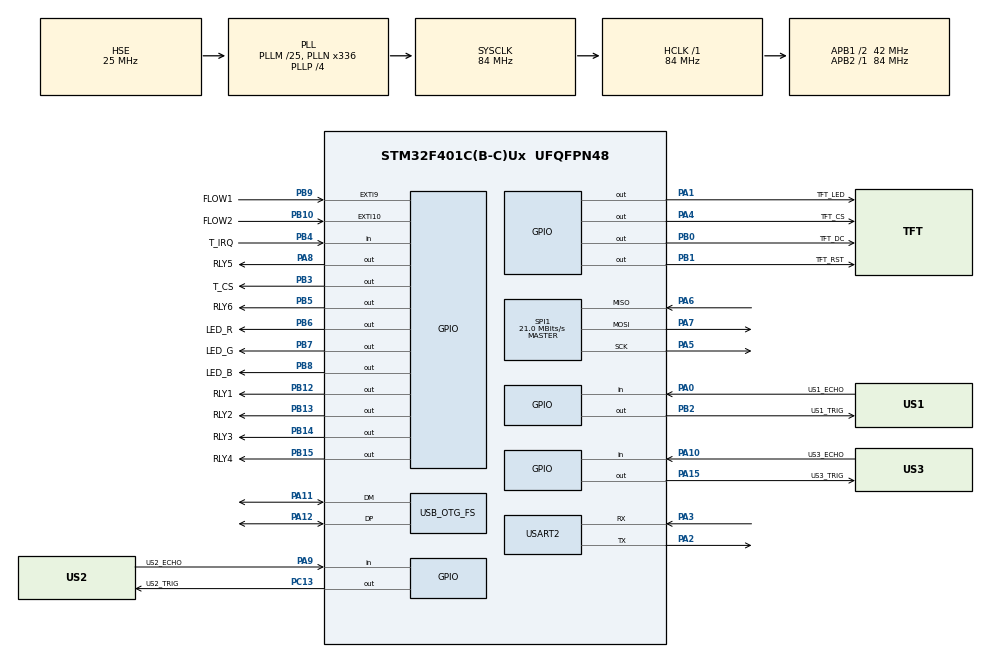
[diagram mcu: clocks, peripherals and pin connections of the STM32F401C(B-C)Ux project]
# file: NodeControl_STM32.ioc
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FREERTOS.Tasks01=defaultTask,0,128,StartDefaultTask,Default,NULL,Dynamic,NULL,NULL;TaskTelemetry,0,512,StartTaskTelemetry,Default,NULL,Dynamic,NULL,NULL;TaskIrrigation,0,512,StartTaskIrrigation,Default,NULL,Dynamic,NULL,NULL
FREERTOS.configUSE_NEWLIB_REENTRANT=1
Mcu.Family=STM32F4
Mcu.Name=STM32F401C(B-C)Ux
Mcu.Package=UFQFPN48
NVIC.EXTI15_10_IRQn=true\:5\:0\:false\:false\:true\:true\:true\:true\:true
NVIC.EXTI9_5_IRQn=true\:5\:0\:false\:false\:true\:true\:true\:true\:true
NVIC.OTG_FS_IRQn=true\:5\:0\:false\:false\:true\:true\:false\:true\:true
NVIC.PriorityGroup=NVIC_PRIORITYGROUP_4
NVIC.TIM5_IRQn=true\:15\:0\:false\:false\:true\:false\:false\:true\:true
NVIC.TimeBase=TIM5_IRQn
NVIC.TimeBaseIP=TIM5
NVIC.USART2_IRQn=true\:5\:0\:false\:false\:true\:true\:true\:true\:true
PA0-WKUP.GPIO_Label=US1_ECHO
PA0-WKUP.Signal=GPIO_Input
PA1.GPIO_Label=TFT_LED
PA1.PinState=GPIO_PIN_SET
PA1.Signal=GPIO_Output
PA10.GPIO_Label=US3_ECHO
PA10.Signal=GPIO_Input
PA11.Mode=Device_Only
PA11.Signal=USB_OTG_FS_DM
PA12.Mode=Device_Only
PA12.Signal=USB_OTG_FS_DP
PA13.Mode=Serial_Wire
PA13.Signal=SYS_JTMS-SWDIO
PA14.Mode=Serial_Wire
PA14.Signal=SYS_JTCK-SWCLK
PA15.GPIO_Label=US3_TRIG
PA15.GPIO_Speed=GPIO_SPEED_FREQ_HIGH
PA15.Signal=GPIO_Output
PA2.Mode=Asynchronous
PA2.Signal=USART2_TX
PA3.Mode=Asynchronous
PA3.Signal=USART2_RX
PA4.GPIO_Label=TFT_CS
PA4.GPIO_Speed=GPIO_SPEED_FREQ_VERY_HIGH
PA4.PinState=GPIO_PIN_SET
PA4.Signal=GPIO_Output
PA5.Mode=Full_Duplex_Master
PA5.Signal=SPI1_SCK
PA6.Mode=Full_Duplex_Master
PA6.Signal=SPI1_MISO
PA7.Mode=Full_Duplex_Master
PA7.Signal=SPI1_MOSI
PA8.GPIO_Label=RLY5
PA8.Signal=GPIO_Output
PA9.GPIO_Label=US2_ECHO
PA9.Signal=GPIO_Input
PB0.GPIO_Label=TFT_DC
PB0.GPIO_Speed=GPIO_SPEED_FREQ_VERY_HIGH
PB0.Signal=GPIO_Output
PB1.GPIO_Label=TFT_RST
PB1.GPIO_Speed=GPIO_SPEED_FREQ_VERY_HIGH
PB1.PinState=GPIO_PIN_SET
PB1.Signal=GPIO_Output
PB10.GPIO_Label=FLOW2
PB10.Signal=GPXTI10
PB12.GPIO_Label=RLY1
PB12.Signal=GPIO_Output
PB13.GPIO_Label=RLY2
PB13.Signal=GPIO_Output
PB14.GPIO_Label=RLY3
PB14.Signal=GPIO_Output
PB15.GPIO_Label=RLY4
PB15.Signal=GPIO_Output
PB2.GPIO_Label=US1_TRIG
PB2.GPIO_Speed=GPIO_SPEED_FREQ_HIGH
PB2.PinState=GPIO_PIN_RESET
PB2.Signal=GPIO_Output
PB3.GPIO_Label=T_CS
PB3.GPIO_Speed=GPIO_SPEED_FREQ_VERY_HIGH
PB3.PinState=GPIO_PIN_SET
PB3.Signal=GPIO_Output
PB4.GPIO_Label=T_IRQ
PB4.Signal=GPIO_Input
PB5.GPIO_Label=RLY6
PB5.Signal=GPIO_Output
PB6.GPIO_Label=LED_R
PB6.Signal=GPIO_Output
PB7.GPIO_Label=LED_G
PB7.Signal=GPIO_Output
PB8.GPIO_Label=LED_B
PB8.Signal=GPIO_Output
PB9.GPIO_Label=FLOW1
PB9.Signal=GPXTI9
PC13-ANTI_TAMP.GPIO_Label=US2_TRIG
PC13-ANTI_TAMP.Signal=GPIO_Output
PH0\ -\ OSC_IN.Mode=HSE-External-Oscillator
PH0\ -\ OSC_IN.Signal=RCC_OSC_IN
PH1\ -\ OSC_OUT.Mode=HSE-External-Oscillator
PH1\ -\ OSC_OUT.Signal=RCC_OSC_OUT
ProjectManager.HeapSize=0x200
ProjectManager.StackSize=0x400
ProjectManager.TargetToolchain=STM32CubeIDE
RCC.48MHZClocksFreq_Value=48000000
RCC.AHBFreq_Value=84000000
RCC.APB1CLKDivider=RCC_HCLK_DIV2
RCC.APB1Freq_Value=42000000
RCC.APB1TimFreq_Value=84000000
RCC.APB2Freq_Value=84000000
RCC.APB2TimFreq_Value=84000000
RCC.CortexFreq_Value=84000000
RCC.HCLKFreq_Value=84000000
RCC.HSE_VALUE=25000000
RCC.HSI_VALUE=16000000
RCC.LSE_VALUE=32768
RCC.PLLM=25
RCC.PLLN=336
RCC.PLLP=RCC_PLLP_DIV4
RCC.PLLQ=7
RCC.SYSCLKFreq_VALUE=84000000
RCC.SYSCLKSource=RCC_SYSCLKSOURCE_PLLCLK
RCC.VCOOutputFreq_Value=336000000
SPI1.BaudRatePrescaler=SPI_BAUDRATEPRESCALER_4
SPI1.CalculateBaudRate=21.0 MBits/s
SPI1.Direction=SPI_DIRECTION_2LINES
SPI1.Mode=SPI_MODE_MASTER
SPI1.VirtualType=VM_MASTER
USART2.VirtualMode=VM_ASYNC
USB_DEVICE.CLASS_NAME_FS=CDC
USB_DEVICE.VirtualMode=Cdc
USB_DEVICE.VirtualModeFS=Cdc_FS
USB_OTG_FS.VirtualMode=Device_Only
VP_FREERTOS_VS_CMSIS_V1.Mode=CMSIS_V1
VP_RTC_VS_RTC_Activate.Mode=RTC_Enabled
VP_SYS_VS_tim5.Mode=TIM5
VP_USB_DEVICE_VS_USB_DEVICE_CDC_FS.Mode=CDC_FS
board=custom

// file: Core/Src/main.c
/* USER CODE BEGIN Header */
/**
  ******************************************************************************
  * @file           : main.c
  * @brief          : Main program body
  ******************************************************************************
  * @attention
  *
  * Copyright (c) 2026 STMicroelectronics.
  * All rights reserved.
  *
  * This software is licensed under terms that can be found in the LICENSE file
  * in the root directory of this software component.
  * If no LICENSE file comes with this software, it is provided AS-IS.
  *
  ******************************************************************************
  */
/* USER CODE END Header */
#include "main.h"
#include "cmsis_os.h"
#include "usb_device.h"

/* USER CODE BEGIN Includes */
#include "app_rtos.h"
/* USER CODE END Includes */

RTC_HandleTypeDef hrtc;

SPI_HandleTypeDef hspi1;

UART_HandleTypeDef huart2;

osThreadId defaultTaskHandle;
osThreadId TaskTelemetryHandle;
osThreadId TaskIrrigationHandle;

void SystemClock_Config(void);
static void MX_GPIO_Init(void);
static void MX_RTC_Init(void);
static void MX_SPI1_Init(void);
static void MX_USART2_UART_Init(void);
void StartDefaultTask(void const * argument);
void StartTaskTelemetry(void const * argument);
void StartTaskIrrigation(void const * argument);

int main(void)
{

  /* MCU Configuration--------------------------------------------------------*/

  /* Reset of all peripherals, Initializes the Flash interface and the Systick. */
  HAL_Init();

  /* Configure the system clock */
  SystemClock_Config();

  /* Initialize all configured peripherals */
  MX_GPIO_Init();
  MX_RTC_Init();
  MX_SPI1_Init();
  MX_USART2_UART_Init();
  /* USER CODE BEGIN 2 */
  App_System_Init();
  /* USER CODE END 2 */

  /* Create the thread(s) */
  /* definition and creation of defaultTask */
  osThreadDef(defaultTask, StartDefaultTask, osPriorityNormal, 0, 128);
  defaultTaskHandle = osThreadCreate(osThread(defaultTask), NULL);

  /* definition and creation of TaskTelemetry */
  osThreadDef(TaskTelemetry, StartTaskTelemetry, osPriorityNormal, 0, 512);
  TaskTelemetryHandle = osThreadCreate(osThread(TaskTelemetry), NULL);

  /* definition and creation of TaskIrrigation */
  osThreadDef(TaskIrrigation, StartTaskIrrigation, osPriorityNormal, 0, 512);
  TaskIrrigationHandle = osThreadCreate(osThread(TaskIrrigation), NULL);

  /* Start scheduler */
  osKernelStart();

  /* We should never get here as control is now taken by the scheduler */

  /* Infinite loop */
  while (1)
  {

  }
}

void SystemClock_Config(void)
{
  RCC_OscInitTypeDef RCC_OscInitStruct = {0};
  RCC_ClkInitTypeDef RCC_ClkInitStruct = {0};

  /** Configure the main internal regulator output voltage
  */
  __HAL_RCC_PWR_CLK_ENABLE();
  __HAL_PWR_VOLTAGESCALING_CONFIG(PWR_REGULATOR_VOLTAGE_SCALE2);

  /** Initializes the RCC Oscillators according to the specified parameters
  * in the RCC_OscInitTypeDef structure.
  */
  RCC_OscInitStruct.OscillatorType = RCC_OSCILLATORTYPE_LSI|RCC_OSCILLATORTYPE_HSE;
  RCC_OscInitStruct.HSEState = RCC_HSE_ON;
  RCC_OscInitStruct.LSIState = RCC_LSI_ON;
  RCC_OscInitStruct.PLL.PLLState = RCC_PLL_ON;
  RCC_OscInitStruct.PLL.PLLSource = RCC_PLLSOURCE_HSE;
  RCC_OscInitStruct.PLL.PLLM = 25;
  RCC_OscInitStruct.PLL.PLLN = 336;
  RCC_OscInitStruct.PLL.PLLP = RCC_PLLP_DIV4;
  RCC_OscInitStruct.PLL.PLLQ = 7;
  if (HAL_RCC_OscConfig(&RCC_OscInitStruct) != HAL_OK)
  {
    Error_Handler();
  }

  /** Initializes the CPU, AHB and APB buses clocks
  */
  RCC_ClkInitStruct.ClockType = RCC_CLOCKTYPE_HCLK|RCC_CLOCKTYPE_SYSCLK
                              |RCC_CLOCKTYPE_PCLK1|RCC_CLOCKTYPE_PCLK2;
  RCC_ClkInitStruct.SYSCLKSource = RCC_SYSCLKSOURCE_PLLCLK;
  RCC_ClkInitStruct.AHBCLKDivider = RCC_SYSCLK_DIV1;
  RCC_ClkInitStruct.APB1CLKDivider = RCC_HCLK_DIV2;
  RCC_ClkInitStruct.APB2CLKDivider = RCC_HCLK_DIV1;

  if (HAL_RCC_ClockConfig(&RCC_ClkInitStruct, FLASH_LATENCY_2) != HAL_OK)
  {
    Error_Handler();
  }
}

static void MX_RTC_Init(void)
{

  /** Initialize RTC Only
  */
  hrtc.Instance = RTC;
  hrtc.Init.HourFormat = RTC_HOURFORMAT_24;
  hrtc.Init.AsynchPrediv = 127;
  hrtc.Init.SynchPrediv = 255;
  hrtc.Init.OutPut = RTC_OUTPUT_DISABLE;
  hrtc.Init.OutPutPolarity = RTC_OUTPUT_POLARITY_HIGH;
  hrtc.Init.OutPutType = RTC_OUTPUT_TYPE_OPENDRAIN;
  if (HAL_RTC_Init(&hrtc) != HAL_OK)
  {
    Error_Handler();
  }

}

static void MX_SPI1_Init(void)
{

  /* SPI1 parameter configuration*/
  hspi1.Instance = SPI1;
  hspi1.Init.Mode = SPI_MODE_MASTER;
  hspi1.Init.Direction = SPI_DIRECTION_2LINES;
  hspi1.Init.DataSize = SPI_DATASIZE_8BIT;
  hspi1.Init.CLKPolarity = SPI_POLARITY_LOW;
  hspi1.Init.CLKPhase = SPI_PHASE_1EDGE;
  hspi1.Init.NSS = SPI_NSS_SOFT;
  hspi1.Init.BaudRatePrescaler = SPI_BAUDRATEPRESCALER_4;
  hspi1.Init.FirstBit = SPI_FIRSTBIT_MSB;
  hspi1.Init.TIMode = SPI_TIMODE_DISABLE;
  hspi1.Init.CRCCalculation = SPI_CRCCALCULATION_DISABLE;
  hspi1.Init.CRCPolynomial = 10;
  if (HAL_SPI_Init(&hspi1) != HAL_OK)
  {
    Error_Handler();
  }

}

static void MX_USART2_UART_Init(void)
{

  huart2.Instance = USART2;
  huart2.Init.BaudRate = 115200;
  huart2.Init.WordLength = UART_WORDLENGTH_8B;
  huart2.Init.StopBits = UART_STOPBITS_1;
  huart2.Init.Parity = UART_PARITY_NONE;
  huart2.Init.Mode = UART_MODE_TX_RX;
  huart2.Init.HwFlowCtl = UART_HWCONTROL_NONE;
  huart2.Init.OverSampling = UART_OVERSAMPLING_16;
  if (HAL_UART_Init(&huart2) != HAL_OK)
  {
    Error_Handler();
  }

}

static void MX_GPIO_Init(void)
{
  GPIO_InitTypeDef GPIO_InitStruct = {0};

  /* GPIO Ports Clock Enable */
  __HAL_RCC_GPIOC_CLK_ENABLE();
  __HAL_RCC_GPIOH_CLK_ENABLE();
  __HAL_RCC_GPIOA_CLK_ENABLE();
  __HAL_RCC_GPIOB_CLK_ENABLE();

  /*Configure GPIO pin Output Level */
  HAL_GPIO_WritePin(US2_TRIG_GPIO_Port, US2_TRIG_Pin, GPIO_PIN_RESET);

  /*Configure GPIO pin Output Level */
  HAL_GPIO_WritePin(GPIOA, TFT_LED_Pin|TFT_CS_Pin, GPIO_PIN_SET);

  /*Configure GPIO pin Output Level */
  HAL_GPIO_WritePin(GPIOB, TFT_DC_Pin|US1_TRIG_Pin|RLY1_Pin|RLY2_Pin
                          |RLY3_Pin|RLY4_Pin|RLY6_Pin|LED_R_Pin
                          |LED_G_Pin|LED_B_Pin, GPIO_PIN_RESET);

  /*Configure GPIO pin Output Level */
  HAL_GPIO_WritePin(GPIOB, TFT_RST_Pin|T_CS_Pin, GPIO_PIN_SET);

  /*Configure GPIO pin Output Level */
  HAL_GPIO_WritePin(GPIOA, RLY5_Pin|US3_TRIG_Pin, GPIO_PIN_RESET);

  /*Configure GPIO pin : US2_TRIG_Pin */
  GPIO_InitStruct.Pin = US2_TRIG_Pin;
  GPIO_InitStruct.Mode = GPIO_MODE_OUTPUT_PP;
  GPIO_InitStruct.Pull = GPIO_NOPULL;
  GPIO_InitStruct.Speed = GPIO_SPEED_FREQ_LOW;
  HAL_GPIO_Init(US2_TRIG_GPIO_Port, &GPIO_InitStruct);

  /*Configure GPIO pins : US1_ECHO_Pin US2_ECHO_Pin US3_ECHO_Pin */
  GPIO_InitStruct.Pin = US1_ECHO_Pin|US2_ECHO_Pin|US3_ECHO_Pin;
  GPIO_InitStruct.Mode = GPIO_MODE_INPUT;
  GPIO_InitStruct.Pull = GPIO_NOPULL;
  HAL_GPIO_Init(GPIOA, &GPIO_InitStruct);

  /*Configure GPIO pins : TFT_LED_Pin RLY5_Pin */
  GPIO_InitStruct.Pin = TFT_LED_Pin|RLY5_Pin;
  GPIO_InitStruct.Mode = GPIO_MODE_OUTPUT_PP;
  GPIO_InitStruct.Pull = GPIO_NOPULL;
  GPIO_InitStruct.Speed = GPIO_SPEED_FREQ_LOW;
  HAL_GPIO_Init(GPIOA, &GPIO_InitStruct);

  /*Configure GPIO pin : TFT_CS_Pin */
  GPIO_InitStruct.Pin = TFT_CS_Pin;
  GPIO_InitStruct.Mode = GPIO_MODE_OUTPUT_PP;
  GPIO_InitStruct.Pull = GPIO_NOPULL;
  GPIO_InitStruct.Speed = GPIO_SPEED_FREQ_VERY_HIGH;
  HAL_GPIO_Init(TFT_CS_GPIO_Port, &GPIO_InitStruct);

  /*Configure GPIO pins : TFT_DC_Pin TFT_RST_Pin T_CS_Pin */
  GPIO_InitStruct.Pin = TFT_DC_Pin|TFT_RST_Pin|T_CS_Pin;
  GPIO_InitStruct.Mode = GPIO_MODE_OUTPUT_PP;
  GPIO_InitStruct.Pull = GPIO_NOPULL;
  GPIO_InitStruct.Speed = GPIO_SPEED_FREQ_VERY_HIGH;
  HAL_GPIO_Init(GPIOB, &GPIO_InitStruct);

  /*Configure GPIO pin : US1_TRIG_Pin */
  GPIO_InitStruct.Pin = US1_TRIG_Pin;
  GPIO_InitStruct.Mode = GPIO_MODE_OUTPUT_PP;
  GPIO_InitStruct.Pull = GPIO_NOPULL;
  GPIO_InitStruct.Speed = GPIO_SPEED_FREQ_HIGH;
  HAL_GPIO_Init(US1_TRIG_GPIO_Port, &GPIO_InitStruct);

  /*Configure GPIO pins : FLOW2_Pin FLOW1_Pin */
  GPIO_InitStruct.Pin = FLOW2_Pin|FLOW1_Pin;
  GPIO_InitStruct.Mode = GPIO_MODE_IT_RISING;
  GPIO_InitStruct.Pull = GPIO_NOPULL;
  HAL_GPIO_Init(GPIOB, &GPIO_InitStruct);

  /*Configure GPIO pins : RLY1_Pin RLY2_Pin RLY3_Pin RLY4_Pin
                           RLY6_Pin LED_R_Pin LED_G_Pin LED_B_Pin */
  GPIO_InitStruct.Pin = RLY1_Pin|RLY2_Pin|RLY3_Pin|RLY4_Pin
                          |RLY6_Pin|LED_R_Pin|LED_G_Pin|LED_B_Pin;
  GPIO_InitStruct.Mode = GPIO_MODE_OUTPUT_PP;
  GPIO_InitStruct.Pull = GPIO_NOPULL;
  GPIO_InitStruct.Speed = GPIO_SPEED_FREQ_LOW;
  HAL_GPIO_Init(GPIOB, &GPIO_InitStruct);

  /*Configure GPIO pin : US3_TRIG_Pin */
  GPIO_InitStruct.Pin = US3_TRIG_Pin;
  GPIO_InitStruct.Mode = GPIO_MODE_OUTPUT_PP;
  GPIO_InitStruct.Pull = GPIO_NOPULL;
  GPIO_InitStruct.Speed = GPIO_SPEED_FREQ_HIGH;
  HAL_GPIO_Init(US3_TRIG_GPIO_Port, &GPIO_InitStruct);

  /*Configure GPIO pin : T_IRQ_Pin */
  GPIO_InitStruct.Pin = T_IRQ_Pin;
  GPIO_InitStruct.Mode = GPIO_MODE_INPUT;
  GPIO_InitStruct.Pull = GPIO_NOPULL;
  HAL_GPIO_Init(T_IRQ_GPIO_Port, &GPIO_InitStruct);

  /* EXTI interrupt init*/
  HAL_NVIC_SetPriority(EXTI9_5_IRQn, 5, 0);
  HAL_NVIC_EnableIRQ(EXTI9_5_IRQn);

  HAL_NVIC_SetPriority(EXTI15_10_IRQn, 5, 0);
  HAL_NVIC_EnableIRQ(EXTI15_10_IRQn);

}

void StartDefaultTask(void const * argument)
{
  /* init code for USB_DEVICE */
  MX_USB_DEVICE_Init();
  for(;;)
  {
    osDelay(1);
  }
}

void StartTaskTelemetry(void const * argument)
{
  /* USER CODE BEGIN StartTaskTelemetry */
	App_TaskTelemetry_Run();
  /* Infinite loop */
  for(;;)
  {
    osDelay(1);
  }
  /* USER CODE END StartTaskTelemetry */
}

void StartTaskIrrigation(void const * argument)
{
  /* USER CODE BEGIN StartTaskIrrigation */
	App_TaskIrrigation_Run();
  /* Infinite loop */
  for(;;)
  {
    osDelay(1);
  }
  /* USER CODE END StartTaskIrrigation */
}

void HAL_TIM_PeriodElapsedCallback(TIM_HandleTypeDef *htim)
{
  if (htim->Instance == TIM5)
  {
    HAL_IncTick();
  }
}

void Error_Handler(void)
{
  __disable_irq();
  while (1)
  {
  }
}
